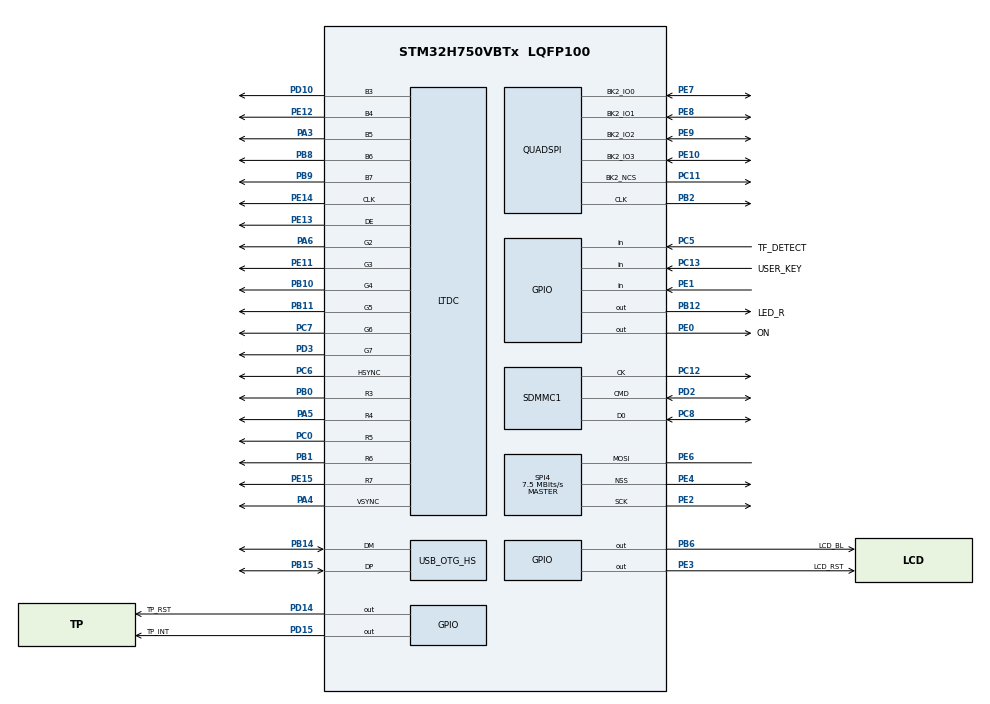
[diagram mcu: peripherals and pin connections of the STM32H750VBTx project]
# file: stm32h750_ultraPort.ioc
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CORTEX_M7.AccessPermission_Spec=MPU_REGION_FULL_ACCESS
CORTEX_M7.BaseAddress_Spec=0x90000000
CORTEX_M7.CPU_DCache=Disabled
CORTEX_M7.CPU_ICache=Enabled
CORTEX_M7.IsBufferable_Spec=MPU_ACCESS_BUFFERABLE
CORTEX_M7.IsCacheable_Spec=MPU_ACCESS_CACHEABLE
CORTEX_M7.Size_Spec=MPU_REGION_SIZE_8MB
CORTEX_M7.SubRegionDisable_Spec=0x0
CORTEX_M7.default_mode_Activation=1
FATFS.BSP.number=1
FATFS.USE_DMA_CODE_SD=0
FATFS._FS_EXFAT=1
FATFS._FS_MINIMIZE=1
FATFS._MAX_SS=4096
FATFS._USE_FIND=1
FATFS._USE_LFN=1
FATFS._USE_MKFS=0
FATFS0.BSP.STBoard=false
FATFS0.BSP.api=Unknown
FATFS0.BSP.instance=PC5
FATFS0.BSP.ip=GPIO
FATFS0.BSP.mode=Input
FATFS0.BSP.name=Detect_SDIO
FATFS0.BSP.solution=PC5
LTDC.ActiveH=480
LTDC.ActiveW=320
LTDC.Alpha0_L0=255
LTDC.Alpha_L0=255
LTDC.Blue=255
LTDC.Blue_L0=255
LTDC.DEPolarity=LTDC_DEPOLARITY_AL
LTDC.HBP=3
LTDC.HFP=15
LTDC.HSPolarity=LTDC_HSPOLARITY_AL
LTDC.HSync=2
LTDC.Layers=0
LTDC.PCPolarity=LTDC_PCPOLARITY_IIPC
LTDC.PixelFormat_L0=LTDC_PIXEL_FORMAT_L8
LTDC.VBP=3
LTDC.VFP=15
LTDC.VSPolarity=LTDC_VSPOLARITY_AL
LTDC.VSync=2
LTDC.WindowX1_L0=0
LTDC.WindowY1_L0=0
Mcu.Family=STM32H7
Mcu.Name=STM32H750VBTx
Mcu.Package=LQFP100
Mdma.MDMA_Channel0.Request0=SDMMC1_END_DATA
Mdma.MDMA_Channel0.RequestsNb=1
Mdma.MDMA_Channel0.SDMMC1_END_DATA.0.BlockCount=0
Mdma.MDMA_Channel0.SDMMC1_END_DATA.0.BlockDataLength=0
Mdma.MDMA_Channel0.SDMMC1_END_DATA.0.BufferTransferLength=1024
Mdma.MDMA_Channel0.SDMMC1_END_DATA.0.CircularMode=MDMA_LINEAR_LIST
Mdma.MDMA_Channel0.SDMMC1_END_DATA.0.DataAlignment=MDMA_DATAALIGN_PACKENABLE
Mdma.MDMA_Channel0.SDMMC1_END_DATA.0.DestBlockAddressOffset=0
Mdma.MDMA_Channel0.SDMMC1_END_DATA.0.DestBurst=MDMA_DEST_BURST_SINGLE
Mdma.MDMA_Channel0.SDMMC1_END_DATA.0.DestDataSize=MDMA_DEST_DATASIZE_BYTE
Mdma.MDMA_Channel0.SDMMC1_END_DATA.0.DestinationInc=MDMA_DEST_INC_BYTE
Mdma.MDMA_Channel0.SDMMC1_END_DATA.0.DstAddress=0
Mdma.MDMA_Channel0.SDMMC1_END_DATA.0.Endianness=MDMA_LITTLE_ENDIANNESS_PRESERVE
Mdma.MDMA_Channel0.SDMMC1_END_DATA.0.Instance=MDMA_Channel0
Mdma.MDMA_Channel0.SDMMC1_END_DATA.0.MaskAddress=0
Mdma.MDMA_Channel0.SDMMC1_END_DATA.0.MaskData=0
Mdma.MDMA_Channel0.SDMMC1_END_DATA.0.Priority=MDMA_PRIORITY_MEDIUM
Mdma.MDMA_Channel0.SDMMC1_END_DATA.0.Rank=First
Mdma.MDMA_Channel0.SDMMC1_END_DATA.0.SourceBlockAddressOffset=0
Mdma.MDMA_Channel0.SDMMC1_END_DATA.0.SourceBurst=MDMA_SOURCE_BURST_SINGLE
Mdma.MDMA_Channel0.SDMMC1_END_DATA.0.SourceDataSize=MDMA_SRC_DATASIZE_BYTE
Mdma.MDMA_Channel0.SDMMC1_END_DATA.0.SourceInc=MDMA_SRC_INC_BYTE
Mdma.MDMA_Channel0.SDMMC1_END_DATA.0.SrcAddress=0
Mdma.MDMA_Channel0.SDMMC1_END_DATA.0.TransferTriggerMode=MDMA_BUFFER_TRANSFER
Mdma.RequestSet0=MDMA_Channel0
Mdma.RequestSetsNb=1
NVIC.MDMA_IRQn=true\:5\:0\:true\:false\:true\:true\:true\:true
NVIC.OTG_HS_IRQn=true\:5\:0\:true\:false\:true\:false\:true\:true
NVIC.PriorityGroup=NVIC_PRIORITYGROUP_4
NVIC.SDMMC1_IRQn=true\:5\:0\:true\:false\:true\:true\:true\:true
NVIC.TIM7_IRQn=true\:15\:0\:true\:false\:true\:true\:true\:true
NVIC.TIM8_UP_TIM13_IRQn=true\:14\:0\:true\:false\:true\:false\:true\:true
NVIC.TimeBase=TIM8_UP_TIM13_IRQn
NVIC.TimeBaseIP=TIM8
PA13\ (JTMS/SWDIO).Mode=Serial_Wire
PA13\ (JTMS/SWDIO).Signal=DEBUG_JTMS-SWDIO
PA14\ (JTCK/SWCLK).Mode=Serial_Wire
PA14\ (JTCK/SWCLK).Signal=DEBUG_JTCK-SWCLK
PA3.GPIO_Speed=GPIO_SPEED_FREQ_VERY_HIGH
PA3.Mode=RGB565
PA3.Signal=LTDC_B5
PA4.GPIO_Speed=GPIO_SPEED_FREQ_VERY_HIGH
PA4.Mode=RGB565
PA4.Signal=LTDC_VSYNC
PA5.GPIO_Speed=GPIO_SPEED_FREQ_VERY_HIGH
PA5.Mode=RGB565
PA5.Signal=LTDC_R4
PA6.GPIO_Speed=GPIO_SPEED_FREQ_VERY_HIGH
PA6.Mode=RGB565
PA6.Signal=LTDC_G2
PB0.GPIO_Speed=GPIO_SPEED_FREQ_VERY_HIGH
PB0.Mode=RGB565
PB0.Signal=LTDC_R3
PB1.GPIO_Speed=GPIO_SPEED_FREQ_VERY_HIGH
PB1.Mode=RGB565
PB1.Signal=LTDC_R6
PB10.GPIO_Speed=GPIO_SPEED_FREQ_VERY_HIGH
PB10.Mode=RGB565
PB10.Signal=LTDC_G4
PB11.GPIO_Speed=GPIO_SPEED_FREQ_VERY_HIGH
PB11.Mode=RGB565
PB11.Signal=LTDC_G5
PB12.GPIO_Label=LED_R
PB12.Signal=GPIO_Output
PB14.Mode=Host_FS
PB14.Signal=USB_OTG_HS_DM
PB15.Mode=Host_FS
PB15.Signal=USB_OTG_HS_DP
PB2.GPIO_Speed=GPIO_SPEED_FREQ_VERY_HIGH
PB2.Mode=Single Bank 2
PB2.Signal=QUADSPI_CLK
PB6.GPIO_Label=LCD_BL
PB6.Signal=GPIO_Output
PB8.GPIO_Speed=GPIO_SPEED_FREQ_VERY_HIGH
PB8.Mode=RGB565
PB8.Signal=LTDC_B6
PB9.GPIO_Speed=GPIO_SPEED_FREQ_VERY_HIGH
PB9.Mode=RGB565
PB9.Signal=LTDC_B7
PC0.GPIO_Speed=GPIO_SPEED_FREQ_VERY_HIGH
PC0.Mode=RGB565
PC0.Signal=LTDC_R5
PC11.GPIO_Speed=GPIO_SPEED_FREQ_VERY_HIGH
PC11.Mode=Single Bank 2
PC11.Signal=QUADSPI_BK2_NCS
PC12.GPIO_PuPd=GPIO_PULLUP
PC12.Mode=SD_1_bit
PC12.Signal=SDMMC1_CK
PC13.GPIO_Label=USER_KEY
PC13.Signal=GPIO_Input
PC5.GPIO_Label=TF_DETECT
PC5.Signal=GPIO_Input
PC6.GPIO_Speed=GPIO_SPEED_FREQ_VERY_HIGH
PC6.Mode=RGB565
PC6.Signal=LTDC_HSYNC
PC7.GPIO_Speed=GPIO_SPEED_FREQ_VERY_HIGH
PC7.Mode=RGB565
PC7.Signal=LTDC_G6
PC8.GPIO_PuPd=GPIO_PULLUP
PC8.Mode=SD_1_bit
PC8.Signal=SDMMC1_D0
PD10.GPIO_Speed=GPIO_SPEED_FREQ_VERY_HIGH
PD10.Mode=RGB565
PD10.Signal=LTDC_B3
PD14.GPIO_Label=TP_RST
PD14.Signal=GPIO_Output
PD15.GPIO_Label=TP_INT
PD15.Signal=GPIO_Output
PD2.GPIO_PuPd=GPIO_PULLUP
PD2.Mode=SD_1_bit
PD2.Signal=SDMMC1_CMD
PD3.GPIO_Speed=GPIO_SPEED_FREQ_VERY_HIGH
PD3.Mode=RGB565
PD3.Signal=LTDC_G7
PE0.GPIO_Label=ON
PE0.Signal=GPIO_Output
PE1.Signal=GPIO_Input
PE10.GPIO_Speed=GPIO_SPEED_FREQ_VERY_HIGH
PE10.Mode=Single Bank 2
PE10.Signal=QUADSPI_BK2_IO3
PE11.GPIO_Speed=GPIO_SPEED_FREQ_VERY_HIGH
PE11.Mode=RGB565
PE11.Signal=LTDC_G3
PE12.GPIO_Speed=GPIO_SPEED_FREQ_VERY_HIGH
PE12.Mode=RGB565
PE12.Signal=LTDC_B4
PE13.GPIO_Speed=GPIO_SPEED_FREQ_VERY_HIGH
PE13.Mode=RGB565
PE13.Signal=LTDC_DE
PE14.GPIO_Speed=GPIO_SPEED_FREQ_VERY_HIGH
PE14.Mode=RGB565
PE14.Signal=LTDC_CLK
PE15.GPIO_Speed=GPIO_SPEED_FREQ_VERY_HIGH
PE15.Mode=RGB565
PE15.Signal=LTDC_R7
PE2.Mode=Simplex_Bidirectional_Master
PE2.Signal=SPI4_SCK
PE3.GPIO_Label=LCD_RST
PE3.GPIO_PuPd=GPIO_PULLDOWN
PE3.Signal=GPIO_Output
PE4.Mode=NSS_Signal_Hard_Output
PE4.Signal=SPI4_NSS
PE6.Mode=Simplex_Bidirectional_Master
PE6.Signal=SPI4_MOSI
PE7.GPIO_Speed=GPIO_SPEED_FREQ_VERY_HIGH
PE7.Mode=Single Bank 2
PE7.Signal=QUADSPI_BK2_IO0
PE8.GPIO_Speed=GPIO_SPEED_FREQ_VERY_HIGH
PE8.Mode=Single Bank 2
PE8.Signal=QUADSPI_BK2_IO1
PE9.GPIO_Speed=GPIO_SPEED_FREQ_VERY_HIGH
PE9.Mode=Single Bank 2
PE9.Signal=QUADSPI_BK2_IO2
PH0-OSC_IN\ (PH0).Mode=HSE-External-Oscillator
PH0-OSC_IN\ (PH0).Signal=RCC_OSC_IN
PH1-OSC_OUT\ (PH1).Mode=HSE-External-Oscillator
PH1-OSC_OUT\ (PH1).Signal=RCC_OSC_OUT
ProjectManager.HeapSize=0x200
ProjectManager.StackSize=0x400
ProjectManager.TargetToolchain=STM32CubeIDE
QUADSPI.ChipSelectHighTime=QSPI_CS_HIGH_TIME_8_CYCLE
QUADSPI.ClockMode=QSPI_CLOCK_MODE_3
QUADSPI.ClockPrescaler=1
QUADSPI.FifoThreshold=32
QUADSPI.FlashSize=22
QUADSPI.SampleShifting=QSPI_SAMPLE_SHIFTING_HALFCYCLE
RCC.ADCFreq_Value=240000000
RCC.APB1Freq_Value=120000000
RCC.APB2Freq_Value=120000000
RCC.APB3Freq_Value=120000000
RCC.APB4Freq_Value=120000000
RCC.CortexFreq_Value=480000000
RCC.D1PPRE=RCC_APB3_DIV2
RCC.D2PPRE1=RCC_APB1_DIV2
RCC.D2PPRE2=RCC_APB2_DIV2
RCC.D3PPRE=RCC_APB4_DIV2
RCC.DIVM1=5
RCC.DIVM2=5
RCC.DIVM3=5
RCC.DIVN1=192
RCC.DIVN2=96
RCC.DIVN3=100
RCC.DIVQ1=120
RCC.DIVQ3=20
RCC.DIVR2=10
RCC.DIVR3=50
RCC.HCLKFreq_Value=240000000
RCC.HPRE=RCC_HCLK_DIV2
RCC.PLLSourceVirtual=RCC_PLLSOURCE_HSE
RCC.SYSCLKFreq_VALUE=480000000
RCC.SYSCLKSource=RCC_SYSCLKSOURCE_PLLCLK
RCC.USBCLockSelection=RCC_USBCLKSOURCE_HSI48
RCC.USBFreq_Value=48000000
SDMMC1.ClockDiv=2
SDMMC1.ClockPowerSave=SDMMC_CLOCK_POWER_SAVE_DISABLE
SDMMC1.HardwareFlowControl=SDMMC_HARDWARE_FLOW_CONTROL_ENABLE
SDMMC1.TransceiverPresent=SDMMC_TRANSCEIVER_NOT_PRESENT
SPI4.BaudRatePrescaler=SPI_BAUDRATEPRESCALER_16
SPI4.CalculateBaudRate=7.5 MBits/s
SPI4.DataSize=SPI_DATASIZE_9BIT
SPI4.Direction=SPI_DIRECTION_1LINE
SPI4.FirstBit=SPI_FIRSTBIT_MSB
SPI4.MasterKeepIOState=SPI_MASTER_KEEP_IO_STATE_ENABLE
SPI4.Mode=SPI_MODE_MASTER
SPI4.NSSPMode=SPI_NSS_PULSE_DISABLE
SPI4.NSSPolarity=SPI_NSS_POLARITY_LOW
SPI4.VirtualNSS=VM_NSSHARD
SPI4.VirtualType=VM_MASTER
TIM7.AutoReloadPreload=TIM_AUTORELOAD_PRELOAD_ENABLE
TIM7.Period=((1000000U / 10000U) - 1U)
TIM7.Prescaler=((2*HAL_RCC_GetPCLK2Freq() / 1000000U) - 1U)
TIM7.TIM_MasterOutputTrigger=TIM_TRGO_RESET
USB_HOST.SW_VBUS_DRIVE_HID_HS=true
USB_HOST.USBH_HandleTypeDef-HID_HS=hUsbHostHS
USB_HOST.USBH_USE_OS-HID_HS=0
USB_HOST.VirtualModeHS=Hid
USB_OTG_HS.VirtualMode-Host_FS=Host_FS
VP_FATFS_VS_SDIO.Mode=SDIO
VP_MEMORYMAP_VS_MEMORYMAP.Mode=CurAppReg
VP_RTC_VS_RTC_Activate.Mode=RTC_Enabled
VP_RTC_VS_RTC_Calendar.Mode=RTC_Calendar
VP_SYS_VS_tim8.Mode=TIM8
VP_TIM7_VS_ClockSourceINT.Mode=Enable_Timer
VP_USB_HOST_VS_USB_HOST_HID_HS.Mode=HID_HS
board=custom

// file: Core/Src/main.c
/* USER CODE BEGIN Header */
/**
  ******************************************************************************
  * @file           : main.c
  * @brief          : Main program body
  ******************************************************************************
  * @attention
  *
  * Copyright (c) 2025 STMicroelectronics.
  * All rights reserved.
  *
  * This software is licensed under terms that can be found in the LICENSE file
  * in the root directory of this software component.
  * If no LICENSE file comes with this software, it is provided AS-IS.
  *
  ******************************************************************************
  */
/* USER CODE END Header */
#include "main.h"
#include "fatfs.h"
#include "mdma.h"
#include "memorymap.h"
#include "rtc.h"
#include "sdmmc.h"
#include "spi.h"
#include "tim.h"
#include "usb_host.h"

/* USER CODE BEGIN Includes */
#include "startup.h"
/* USER CODE END Includes */

void SystemClock_Config(void);
static void MPU_Config(void);
void MX_USB_HOST_Process(void);

int main(void)
{

  /* MPU Configuration--------------------------------------------------------*/
  MPU_Config();

  /* Enable the CPU Cache */

  /* Enable I-Cache---------------------------------------------------------*/
  SCB_EnableICache();

  /* MCU Configuration--------------------------------------------------------*/

  /* Reset of all peripherals, Initializes the Flash interface and the Systick. */
  HAL_Init();

  /* Configure the system clock */
  SystemClock_Config();

  /* USER CODE BEGIN SysInit */
  initialize();
  /* USER CODE END SysInit */

  /* Initialize all configured peripherals */
  MX_MDMA_Init();
  MX_SDMMC1_SD_Init();
  MX_FATFS_Init();
  MX_USB_HOST_Init();
  MX_SPI4_Init();
  MX_RTC_Init();
  MX_TIM7_Init();
  /* USER CODE BEGIN 2 */
  setup();
  /* USER CODE END 2 */

  /* Infinite loop */
  /* USER CODE BEGIN WHILE */
  while (1)
  {
	loop();
	continue;
    /* USER CODE END WHILE */
    MX_USB_HOST_Process();

  }
}

void SystemClock_Config(void)
{
  RCC_OscInitTypeDef RCC_OscInitStruct = {0};
  RCC_ClkInitTypeDef RCC_ClkInitStruct = {0};

  /** Supply configuration update enable
  */
  HAL_PWREx_ConfigSupply(PWR_LDO_SUPPLY);

  /** Configure the main internal regulator output voltage
  */
  __HAL_PWR_VOLTAGESCALING_CONFIG(PWR_REGULATOR_VOLTAGE_SCALE0);

  while(!__HAL_PWR_GET_FLAG(PWR_FLAG_VOSRDY)) {}

  /** Initializes the RCC Oscillators according to the specified parameters
  * in the RCC_OscInitTypeDef structure.
  */
  RCC_OscInitStruct.OscillatorType = RCC_OSCILLATORTYPE_HSI48|RCC_OSCILLATORTYPE_LSI
                              |RCC_OSCILLATORTYPE_HSE;
  RCC_OscInitStruct.HSEState = RCC_HSE_ON;
  RCC_OscInitStruct.LSIState = RCC_LSI_ON;
  RCC_OscInitStruct.HSI48State = RCC_HSI48_ON;
  RCC_OscInitStruct.PLL.PLLState = RCC_PLL_ON;
  RCC_OscInitStruct.PLL.PLLSource = RCC_PLLSOURCE_HSE;
  RCC_OscInitStruct.PLL.PLLM = 5;
  RCC_OscInitStruct.PLL.PLLN = 192;
  RCC_OscInitStruct.PLL.PLLP = 2;
  RCC_OscInitStruct.PLL.PLLQ = 120;
  RCC_OscInitStruct.PLL.PLLR = 2;
  RCC_OscInitStruct.PLL.PLLRGE = RCC_PLL1VCIRANGE_2;
  RCC_OscInitStruct.PLL.PLLVCOSEL = RCC_PLL1VCOWIDE;
  RCC_OscInitStruct.PLL.PLLFRACN = 0;
  if (HAL_RCC_OscConfig(&RCC_OscInitStruct) != HAL_OK)
  {
    Error_Handler();
  }

  /** Initializes the CPU, AHB and APB buses clocks
  */
  RCC_ClkInitStruct.ClockType = RCC_CLOCKTYPE_HCLK|RCC_CLOCKTYPE_SYSCLK
                              |RCC_CLOCKTYPE_PCLK1|RCC_CLOCKTYPE_PCLK2
                              |RCC_CLOCKTYPE_D3PCLK1|RCC_CLOCKTYPE_D1PCLK1;
  RCC_ClkInitStruct.SYSCLKSource = RCC_SYSCLKSOURCE_PLLCLK;
  RCC_ClkInitStruct.SYSCLKDivider = RCC_SYSCLK_DIV1;
  RCC_ClkInitStruct.AHBCLKDivider = RCC_HCLK_DIV2;
  RCC_ClkInitStruct.APB3CLKDivider = RCC_APB3_DIV2;
  RCC_ClkInitStruct.APB1CLKDivider = RCC_APB1_DIV2;
  RCC_ClkInitStruct.APB2CLKDivider = RCC_APB2_DIV2;
  RCC_ClkInitStruct.APB4CLKDivider = RCC_APB4_DIV2;

  if (HAL_RCC_ClockConfig(&RCC_ClkInitStruct, FLASH_LATENCY_4) != HAL_OK)
  {
    Error_Handler();
  }
}

 /* MPU Configuration */

void MPU_Config(void)
{
  MPU_Region_InitTypeDef MPU_InitStruct = {0};

  /* Disables the MPU */
  HAL_MPU_Disable();

  /** Initializes and configures the Region and the memory to be protected
  */
  MPU_InitStruct.Enable = MPU_REGION_ENABLE;
  MPU_InitStruct.Number = MPU_REGION_NUMBER0;
  MPU_InitStruct.BaseAddress = 0x90000000;
  MPU_InitStruct.Size = MPU_REGION_SIZE_8MB;
  MPU_InitStruct.SubRegionDisable = 0x0;
  MPU_InitStruct.TypeExtField = MPU_TEX_LEVEL0;
  MPU_InitStruct.AccessPermission = MPU_REGION_FULL_ACCESS;
  MPU_InitStruct.DisableExec = MPU_INSTRUCTION_ACCESS_DISABLE;
  MPU_InitStruct.IsShareable = MPU_ACCESS_SHAREABLE;
  MPU_InitStruct.IsCacheable = MPU_ACCESS_CACHEABLE;
  MPU_InitStruct.IsBufferable = MPU_ACCESS_BUFFERABLE;

  HAL_MPU_ConfigRegion(&MPU_InitStruct);
  /* Enables the MPU */
  HAL_MPU_Enable(MPU_PRIVILEGED_DEFAULT);

}

void HAL_TIM_PeriodElapsedCallback(TIM_HandleTypeDef *htim)
{
  if (htim->Instance == TIM8)
  {
    HAL_IncTick();
  }
  /* USER CODE BEGIN Callback 1 */
  if (htim->Instance == TIM7)
  {
	  MX_USB_HOST_Process();
  }
  /* USER CODE END Callback 1 */
}

void Error_Handler(void)
{
  __disable_irq();
  while (1)
  {
  }
}
